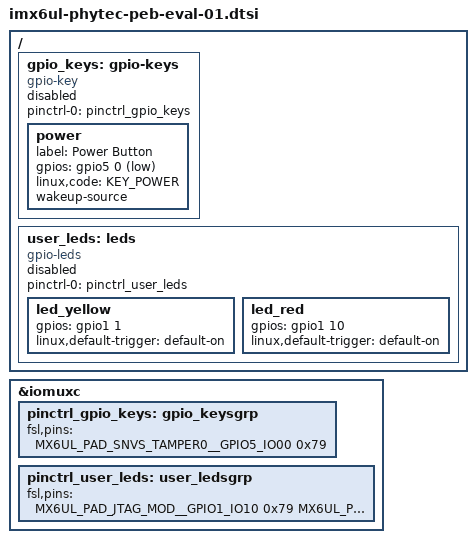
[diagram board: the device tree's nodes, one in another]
// SPDX-License-Identifier: GPL-2.0
/*
 * Copyright (C) 2016 PHYTEC Messtechnik
 * Author: Christian Hemp <c.hemp@phytec.de>
 */

#include <dt-bindings/input/input.h>

/ {
	gpio_keys: gpio-keys {
		compatible = "gpio-key";
		pinctrl-names = "default";
		pinctrl-0 = <&pinctrl_gpio_keys>;
		status = "disabled";

		power {
			label = "Power Button";
			gpios = <&gpio5 0 GPIO_ACTIVE_LOW>;
			linux,code = <KEY_POWER>;
			wakeup-source;
		};
	};

	user_leds: leds {
		compatible = "gpio-leds";
		pinctrl-names = "default";
		pinctrl-0 = <&pinctrl_user_leds>;
		status = "disabled";

		led_yellow {
			gpios = <&gpio1 1 GPIO_ACTIVE_HIGH>;
			linux,default-trigger = "default-on";
		};

		led_red {
			gpios = <&gpio1 10 GPIO_ACTIVE_HIGH>;
			linux,default-trigger = "default-on";
		};
	};
};

&iomuxc {
	pinctrl_gpio_keys: gpio_keysgrp {
		fsl,pins = <
			MX6UL_PAD_SNVS_TAMPER0__GPIO5_IO00	0x79
		>;
	};

	pinctrl_user_leds: user_ledsgrp {
		fsl,pins = <
			MX6UL_PAD_JTAG_MOD__GPIO1_IO10		0x79
			MX6UL_PAD_GPIO1_IO01__GPIO1_IO01	0x79
		>;
	};
};
